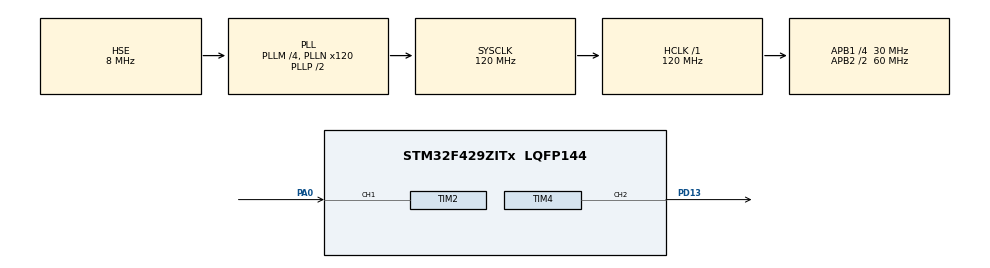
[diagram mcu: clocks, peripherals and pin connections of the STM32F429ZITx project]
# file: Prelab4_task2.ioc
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Mcu.Family=STM32F4
Mcu.Name=STM32F429ZITx
Mcu.Package=LQFP144
NVIC.PriorityGroup=NVIC_PRIORITYGROUP_4
NVIC.TIM2_IRQn=true\:0\:0\:false\:false\:true\:true\:true\:true
NVIC.TIM4_IRQn=true\:0\:0\:false\:false\:true\:true\:true\:true
PA0/WKUP.Signal=S_TIM2_CH1_ETR
PD13.Signal=S_TIM4_CH2
PH0/OSC_IN.Mode=HSE-External-Oscillator
PH0/OSC_IN.Signal=RCC_OSC_IN
PH1/OSC_OUT.Mode=HSE-External-Oscillator
PH1/OSC_OUT.Signal=RCC_OSC_OUT
ProjectManager.HeapSize=0x200
ProjectManager.StackSize=0x400
ProjectManager.TargetToolchain=EWARM V8.50
RCC.48MHZClocksFreq_Value=60000000
RCC.AHBFreq_Value=120000000
RCC.APB1CLKDivider=RCC_HCLK_DIV4
RCC.APB1Freq_Value=30000000
RCC.APB1TimFreq_Value=60000000
RCC.APB2CLKDivider=RCC_HCLK_DIV2
RCC.APB2Freq_Value=60000000
RCC.APB2TimFreq_Value=120000000
RCC.CortexFreq_Value=120000000
RCC.HCLKFreq_Value=120000000
RCC.HSE_VALUE=8000000
RCC.HSI_VALUE=16000000
RCC.LSE_VALUE=32768
RCC.PLLM=4
RCC.PLLN=120
RCC.PLLSourceVirtual=RCC_PLLSOURCE_HSE
RCC.SYSCLKFreq_VALUE=120000000
RCC.SYSCLKSource=RCC_SYSCLKSOURCE_PLLCLK
RCC.VCOOutputFreq_Value=240000000
SH.S_TIM2_CH1_ETR.0=TIM2_CH1,Input_Capture1_from_TI1
SH.S_TIM4_CH2.0=TIM4_CH2,Output Compare2 CH2
TIM2.Channel-Input_Capture1_from_TI1=TIM_CHANNEL_1
TIM2.ICPolarity_CH1=TIM_INPUTCHANNELPOLARITY_BOTHEDGE
TIM4.Channel-Output\ Compare2\ CH2=TIM_CHANNEL_2
TIM4.OCMode_2=TIM_OCMODE_TOGGLE
VP_TIM2_VS_ClockSourceINT.Mode=Internal
VP_TIM4_VS_ClockSourceINT.Mode=Internal
board=custom

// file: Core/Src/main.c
/* USER CODE BEGIN Header */
/**
  ******************************************************************************
  * @file           : main.c
  * @brief          : Main program body
  ******************************************************************************
  * @attention
  *
  * Copyright (c) 2023 STMicroelectronics.
  * All rights reserved.
  *
  * This software is licensed under terms that can be found in the LICENSE file
  * in the root directory of this software component.
  * If no LICENSE file comes with this software, it is provided AS-IS.
  *
  ******************************************************************************
  */
/* USER CODE END Header */
#include "main.h"
#include "stdio.h"

TIM_HandleTypeDef htim2;
TIM_HandleTypeDef htim4;

/* USER CODE BEGIN PV */
float highPulse = 0;
float period; // period in seconds
float width; // pulse width in seconds
int countAtRisingEdge; // timer count at rising edge
/* USER CODE END PV */

void SystemClock_Config(void);
static void MX_GPIO_Init(void);
static void MX_TIM4_Init(void);
static void MX_TIM2_Init(void);

int main(void)
{

  /* MCU Configuration--------------------------------------------------------*/

  /* Reset of all peripherals, Initializes the Flash interface and the Systick. */
  HAL_Init();

  /* Configure the system clock */
  SystemClock_Config();

  /* Initialize all configured peripherals */
  MX_GPIO_Init();
  MX_TIM4_Init();
  MX_TIM2_Init();

  /* Infinite loop */
  /* USER CODE BEGIN WHILE */
  TIM4->ARR = 0xffff;
  TIM4->CCR2 = 2400;
  HAL_TIM_OC_Start_IT(&htim4, TIM_CHANNEL_2); // Start TIM4 in output compare mode
  HAL_TIM_IC_Start_IT(&htim2, TIM_CHANNEL_1); // Start TIM2 in input capture mode channel 1
  while (1)
  {
    printf("Pulse width %.2f us\n", width);
    printf("Period time %.2f us\n\n", period);

    /* USER CODE END WHILE */

  }
}

void SystemClock_Config(void)
{
  RCC_OscInitTypeDef RCC_OscInitStruct = {0};
  RCC_ClkInitTypeDef RCC_ClkInitStruct = {0};

  /** Configure the main internal regulator output voltage
  */
  __HAL_RCC_PWR_CLK_ENABLE();
  __HAL_PWR_VOLTAGESCALING_CONFIG(PWR_REGULATOR_VOLTAGE_SCALE3);

  /** Initializes the RCC Oscillators according to the specified parameters
  * in the RCC_OscInitTypeDef structure.
  */
  RCC_OscInitStruct.OscillatorType = RCC_OSCILLATORTYPE_HSE;
  RCC_OscInitStruct.HSEState = RCC_HSE_ON;
  RCC_OscInitStruct.PLL.PLLState = RCC_PLL_ON;
  RCC_OscInitStruct.PLL.PLLSource = RCC_PLLSOURCE_HSE;
  RCC_OscInitStruct.PLL.PLLM = 4;
  RCC_OscInitStruct.PLL.PLLN = 120;
  RCC_OscInitStruct.PLL.PLLP = RCC_PLLP_DIV2;
  RCC_OscInitStruct.PLL.PLLQ = 4;
  if (HAL_RCC_OscConfig(&RCC_OscInitStruct) != HAL_OK)
  {
    Error_Handler();
  }

  /** Initializes the CPU, AHB and APB buses clocks
  */
  RCC_ClkInitStruct.ClockType = RCC_CLOCKTYPE_HCLK|RCC_CLOCKTYPE_SYSCLK
                              |RCC_CLOCKTYPE_PCLK1|RCC_CLOCKTYPE_PCLK2;
  RCC_ClkInitStruct.SYSCLKSource = RCC_SYSCLKSOURCE_PLLCLK;
  RCC_ClkInitStruct.AHBCLKDivider = RCC_SYSCLK_DIV1;
  RCC_ClkInitStruct.APB1CLKDivider = RCC_HCLK_DIV4;
  RCC_ClkInitStruct.APB2CLKDivider = RCC_HCLK_DIV2;

  if (HAL_RCC_ClockConfig(&RCC_ClkInitStruct, FLASH_LATENCY_3) != HAL_OK)
  {
    Error_Handler();
  }
}

static void MX_TIM2_Init(void)
{

  TIM_ClockConfigTypeDef sClockSourceConfig = {0};
  TIM_MasterConfigTypeDef sMasterConfig = {0};
  TIM_IC_InitTypeDef sConfigIC = {0};

  htim2.Instance = TIM2;
  htim2.Init.Prescaler = 0;
  htim2.Init.CounterMode = TIM_COUNTERMODE_UP;
  htim2.Init.Period = 4294967295;
  htim2.Init.ClockDivision = TIM_CLOCKDIVISION_DIV1;
  htim2.Init.AutoReloadPreload = TIM_AUTORELOAD_PRELOAD_DISABLE;
  if (HAL_TIM_Base_Init(&htim2) != HAL_OK)
  {
    Error_Handler();
  }
  sClockSourceConfig.ClockSource = TIM_CLOCKSOURCE_INTERNAL;
  if (HAL_TIM_ConfigClockSource(&htim2, &sClockSourceConfig) != HAL_OK)
  {
    Error_Handler();
  }
  if (HAL_TIM_IC_Init(&htim2) != HAL_OK)
  {
    Error_Handler();
  }
  sMasterConfig.MasterOutputTrigger = TIM_TRGO_RESET;
  sMasterConfig.MasterSlaveMode = TIM_MASTERSLAVEMODE_DISABLE;
  if (HAL_TIMEx_MasterConfigSynchronization(&htim2, &sMasterConfig) != HAL_OK)
  {
    Error_Handler();
  }
  sConfigIC.ICPolarity = TIM_INPUTCHANNELPOLARITY_BOTHEDGE;
  sConfigIC.ICSelection = TIM_ICSELECTION_DIRECTTI;
  sConfigIC.ICPrescaler = TIM_ICPSC_DIV1;
  sConfigIC.ICFilter = 0;
  if (HAL_TIM_IC_ConfigChannel(&htim2, &sConfigIC, TIM_CHANNEL_1) != HAL_OK)
  {
    Error_Handler();
  }

}

static void MX_TIM4_Init(void)
{

  TIM_ClockConfigTypeDef sClockSourceConfig = {0};
  TIM_MasterConfigTypeDef sMasterConfig = {0};
  TIM_OC_InitTypeDef sConfigOC = {0};

  htim4.Instance = TIM4;
  htim4.Init.Prescaler = 0;
  htim4.Init.CounterMode = TIM_COUNTERMODE_UP;
  htim4.Init.Period = 65535;
  htim4.Init.ClockDivision = TIM_CLOCKDIVISION_DIV1;
  htim4.Init.AutoReloadPreload = TIM_AUTORELOAD_PRELOAD_DISABLE;
  if (HAL_TIM_Base_Init(&htim4) != HAL_OK)
  {
    Error_Handler();
  }
  sClockSourceConfig.ClockSource = TIM_CLOCKSOURCE_INTERNAL;
  if (HAL_TIM_ConfigClockSource(&htim4, &sClockSourceConfig) != HAL_OK)
  {
    Error_Handler();
  }
  if (HAL_TIM_OC_Init(&htim4) != HAL_OK)
  {
    Error_Handler();
  }
  sMasterConfig.MasterOutputTrigger = TIM_TRGO_RESET;
  sMasterConfig.MasterSlaveMode = TIM_MASTERSLAVEMODE_DISABLE;
  if (HAL_TIMEx_MasterConfigSynchronization(&htim4, &sMasterConfig) != HAL_OK)
  {
    Error_Handler();
  }
  sConfigOC.OCMode = TIM_OCMODE_TOGGLE;
  sConfigOC.Pulse = 0;
  sConfigOC.OCPolarity = TIM_OCPOLARITY_HIGH;
  sConfigOC.OCFastMode = TIM_OCFAST_DISABLE;
  if (HAL_TIM_OC_ConfigChannel(&htim4, &sConfigOC, TIM_CHANNEL_2) != HAL_OK)
  {
    Error_Handler();
  }
  HAL_TIM_MspPostInit(&htim4);

}

static void MX_GPIO_Init(void)
{

  /* GPIO Ports Clock Enable */
  __HAL_RCC_GPIOH_CLK_ENABLE();
  __HAL_RCC_GPIOA_CLK_ENABLE();
  __HAL_RCC_GPIOD_CLK_ENABLE();

}

void Error_Handler(void)
{
  __disable_irq();
  while (1)
  {
  }
}
